# ATSAM4LC4C register map
Vendor: Atmel Corporation; Series: SAM4L; File version: B
CPU: CM4 r0p1, little endian, MPU, no FPU, 4 interrupt priority bits
Registers are 32-bit, write-only, reset 0x0 unless marked. A register's access mark holds for its fields unless they carry their own. Offsets are from the block's base; [hi:lo] are bit positions; {n}, {i} and the like mark numbered series.

## CATB — Capacitive Touch Module B
Base 0x40070000; register names take the prefix CATB_
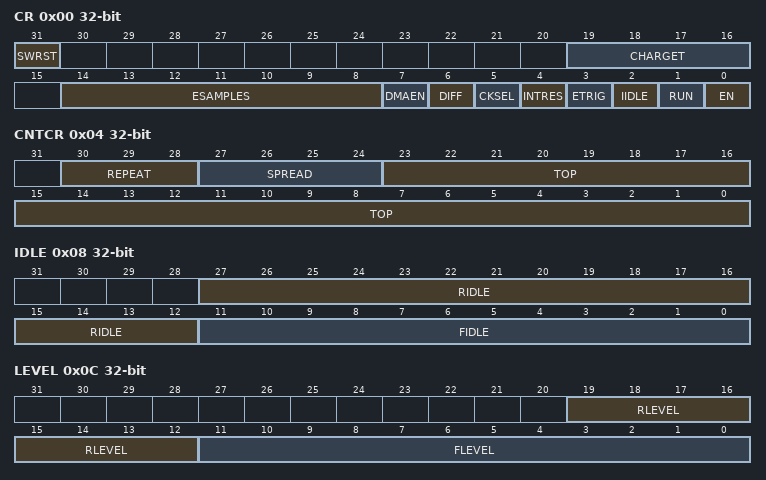
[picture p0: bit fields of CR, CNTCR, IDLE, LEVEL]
0x00 CR rw — Control Register
  [31] SWRST — Software Reset
  [19:16] CHARGET — Charge Time
  [14:8] ESAMPLES — Number of Event Samples
  [7] DMAEN — DMA Enable
  [6] DIFF — Differential Mode
  [5] CKSEL — Clock Select
  [4] INTRES — Internal Resistors
  [3] ETRIG — Event Triggered Operation
  [2] IIDLE — Initialize Idle Value
  [1] RUN — Start Operation
  [0] EN — Module Enable
0x04 CNTCR rw — Counter Control Register
  [30:28] REPEAT — Repeat Measurements
  [27:24] SPREAD — Spread Spectrum
  [23:0] TOP — Counter Top Value
0x08 IDLE rw — Sensor Idle Level
  [27:12] RIDLE — Integer Sensor Idle
  [11:0] FIDLE — Fractional Sensor Idle
0x0C LEVEL ro — Sensor Relative Level
  [19:12] RLEVEL — Integer Sensor Level
  [11:0] FLEVEL — Fractional Sensor Level
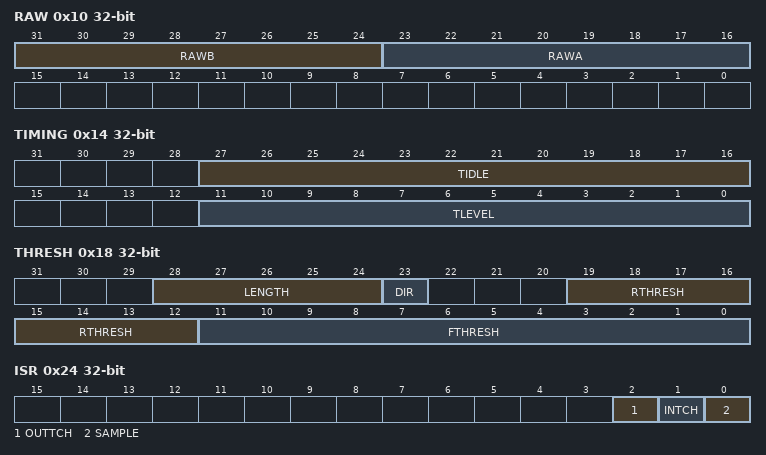
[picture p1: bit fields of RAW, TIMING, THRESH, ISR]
0x10 RAW ro — Sensor Raw Value
  [31:24] RAWB — Last Sensor Raw Value
  [23:16] RAWA — Current Sensor Raw Value
0x14 TIMING rw — Filter Timing Register
  [27:16] TIDLE — Idle Smoothening
  [11:0] TLEVEL — Relative Level Smoothing
0x18 THRESH rw — Threshold Register
  [28:24] LENGTH — Threshold Length
  [23] DIR — Threshold Direction
  [19:12] RTHRESH — Rational part of Threshold Value
  [11:0] FTHRESH — Fractional part of Threshold Value
0x1C PINSEL rw — Pin Selection Register
  [7:0] PINSEL — Pin Select
0x20 DMA rw — Direct Memory Access Register
  [31:0] DMA — Direct Memory Access
0x24 ISR ro — Interrupt Status Register
  [2] OUTTCH — Out-of-Touch Interrupt Status
  [1] INTCH — In-touch Interrupt Status
  [0] SAMPLE — Sample Ready Interrupt Status
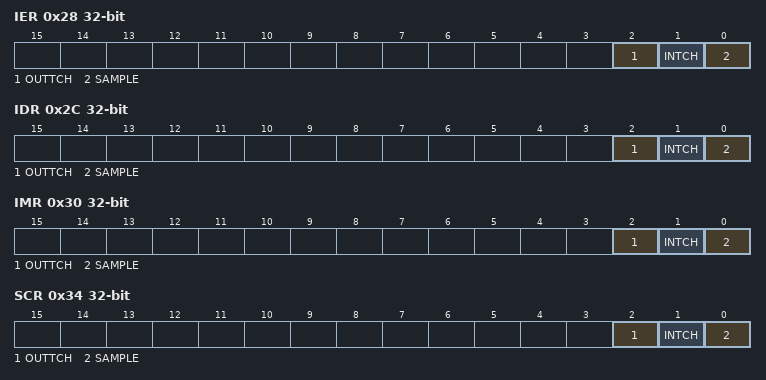
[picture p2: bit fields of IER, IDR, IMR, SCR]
0x28 IER — Interrupt Enable Register
  [2] OUTTCH — Out-of-Touch Interrupt Enable
  [1] INTCH — In-touch Interrupt Enable
  [0] SAMPLE — Sample Ready Interrupt Enable
0x2C IDR — Interrupt Disable Register
  [2] OUTTCH — Out-of-Touch Interrupt Disable
  [1] INTCH — In-touch Interrupt Disable
  [0] SAMPLE — Sample Ready Interrupt Disable
0x30 IMR ro — Interrupt Mask Register
  [2] OUTTCH — Out-of-Touch Interrupt Mask
  [1] INTCH — In-touch Interrupt Mask
  [0] SAMPLE — Sample Ready Interrupt Mask
0x34 SCR — Status Clear Register
  [2] OUTTCH — Out-of-Touch
  [1] INTCH — In-touch
  [0] SAMPLE — Sample Ready
{0x40+4i} INTCH{i} (i=0..0) ro — In-Touch Status Register
  [31:0] INTCH — In-Touch
{0x50+4i} INTCHCLR{i} (i=0..0) — In-Touch Status Clear Register
  [31:0] INTCHCLR — In-Touch Clear
{0x60+4i} OUTTCH{i} (i=0..0) ro — Out-of-Touch Status Register
  [31:0] OUTTCH — Out-of-Touch
{0x70+4i} OUTTCHCLR{i} (i=0..0) — Out-of-Touch Status Clear Register
  [31:0] OUTTCHCLR — Out of Touch
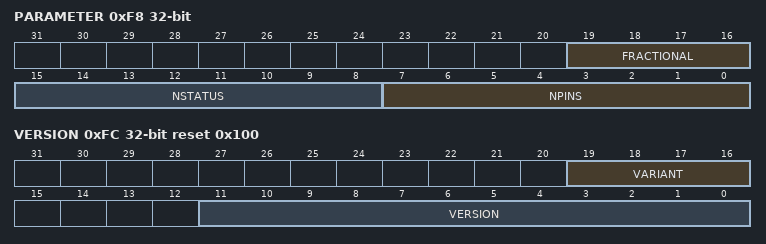
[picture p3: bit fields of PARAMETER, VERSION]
0xF8 PARAMETER ro
  [19:16] FRACTIONAL — Number of Fractional bits
  [15:8] NSTATUS — Number of Status bits
  [7:0] NPINS — Number of Pins
0xFC VERSION ro reset 0x100
  [19:16] VARIANT — Variant number
  [11:0] VERSION — Version number

## CHIPID — Chip ID Registers
Base 0x400E0400; register names take the prefix CHIPID_
0x340 CIDR ro reset 0xAB0A09E0 — Chip ID Register
0x344 EXID ro reset 0x400000F — Chip ID Extension Register

## CRCCU — CRC Calculation Unit
Base 0x400A4000; register names take the prefix CRCCU_
0x00 DSCR rw — Descriptor Base Register
  [31:9] DSCR — Description Base Address
0x08 DMAEN — DMA Enable Register
  [0] DMAEN — DMA Enable
0x0C DMADIS — DMA Disable Register
  [0] DMADIS — DMA Disable
0x10 DMASR ro — DMA Status Register
  [0] DMASR — DMA Channel Status
0x14 DMAIER — DMA Interrupt Enable Register
  [0] DMAIER — DMA Interrupt Enable
0x18 DMAIDR — DMA Interrupt Disable Register
  [0] DMAIDR — DMA Interrupt Disable
0x1C DMAIMR ro — DMA Interrupt Mask Register
  [0] DMAIMR wo — DMA Interrupt Mask
0x20 DMAISR ro — DMA Interrupt Status Register
  [0] DMAISR — DMA Interrupt Status
0x34 CR — Control Register
  [0] RESET — Reset CRCComputation
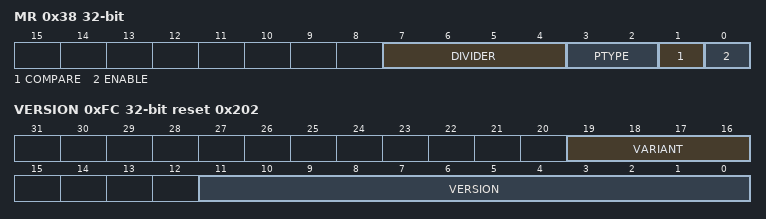
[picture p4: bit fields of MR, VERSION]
0x38 MR rw — Mode Register
  [7:4] DIVIDER — Bandwidth Divider
  [3:2] PTYPE — Polynomial Type
    0=CCITT8023; 1=CASTAGNOLI; 2=CCITT16
  [1] COMPARE — CRC Compare
  [0] ENABLE — CRC Computation Enable
0x3C SR ro reset 0xFFFFFFFF — Status Register
  [31:0] CRC — Cyclic Redundancy Check Value
0x40 IER — Interrupt Enable Register
  [0] ERRIER — CRC Error Interrupt Enable
0x44 IDR — Interrupt Disable Register
  [0] ERRIDR — CRC Error Interrupt Disable
0x48 IMR ro — Interrupt Mask Register
  [0] ERRIMR — CRC Error Interrupt Mask
0x4C ISR ro — Interrupt Status Register
  [0] ERRISR — CRC Error Interrupt Status
0xFC VERSION ro reset 0x202
  [19:16] VARIANT — Variant Number
  [11:0] VERSION — Version Number
